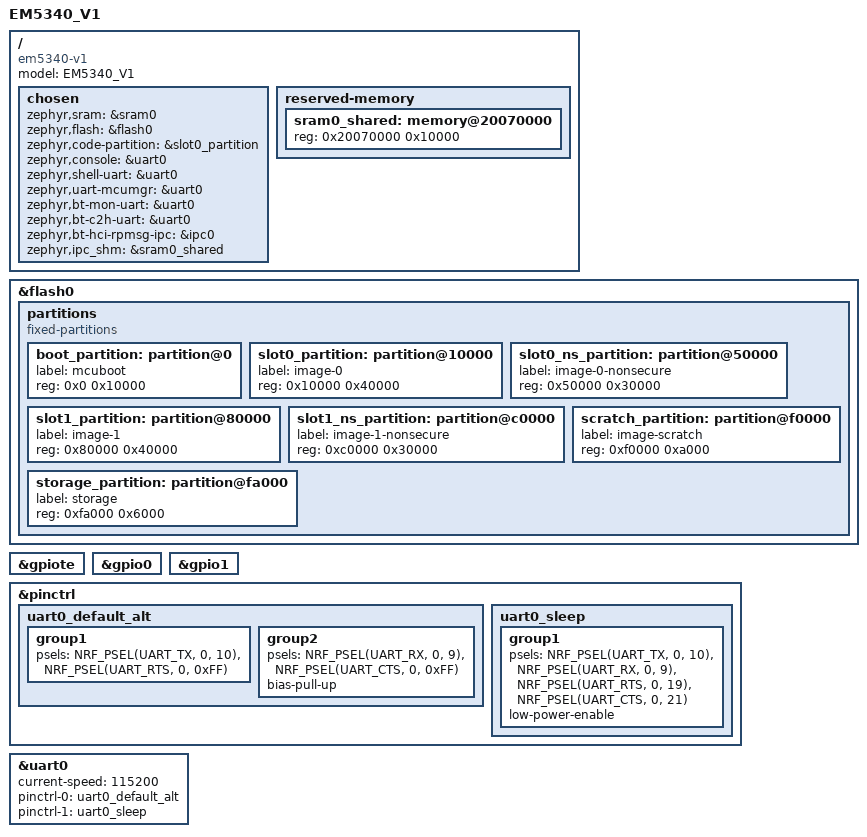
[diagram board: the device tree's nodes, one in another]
// Copyright (c) 2022 Nordic Semiconductor ASA
// SPDX-License-Identifier: Apache-2.0

/dts-v1/;
#include <nordic/nrf5340_cpuapp_qkaa.dtsi>

/ {
	model = "EM5340_V1";
	compatible = "em5340-v1";

	chosen {
		zephyr,sram = &sram0;
		zephyr,flash = &flash0;
		zephyr,code-partition = &slot0_partition;
		zephyr,console = &uart0;
		zephyr,shell-uart = &uart0;
		zephyr,uart-mcumgr = &uart0;
		zephyr,bt-mon-uart = &uart0;
		zephyr,bt-c2h-uart = &uart0;
		zephyr,bt-hci-rpmsg-ipc = &ipc0;
	};
};

/ {
	chosen {
		/* shared memory reserved for the inter-processor communication */
		zephyr,ipc_shm = &sram0_shared;
	};

	reserved-memory {
		#address-cells = <1>;
		#size-cells = <1>;
		ranges;

		sram0_shared: memory@20070000 {
			/* SRAM allocated to shared memory */
			reg = <0x20070000 0x10000>;
		};
	};
};

&flash0 {
	partitions {
		compatible = "fixed-partitions";
		#address-cells = <1>;
		#size-cells = <1>;

		boot_partition: partition@0 {
			label = "mcuboot";
			reg = <0x0 0x10000>;
		};
		slot0_partition: partition@10000 {
			label = "image-0";
			reg = <0x10000 0x40000>;
		};
		slot0_ns_partition: partition@50000 {
			label = "image-0-nonsecure";
			reg = <0x50000 0x30000>;
		};
		slot1_partition: partition@80000 {
			label = "image-1";
			reg = <0x80000 0x40000>;
		};
		slot1_ns_partition: partition@c0000 {
			label = "image-1-nonsecure";
			reg = <0xc0000 0x30000>;
		};
		scratch_partition: partition@f0000 {
			label = "image-scratch";
			reg = <0xf0000 0xa000>;
		};
		storage_partition: partition@fa000 {
			label = "storage";
			reg = <0xfa000 0x6000>;
		};
	};
};

&gpiote {
	status = "okay";
};

&gpio0 {
	status = "okay";
};

&gpio1 {
	status = "okay";
};

&pinctrl {
    uart0_default_alt: uart0_default_alt {
        group1 {
			psels = <NRF_PSEL(UART_TX, 0, 10)>,
				<NRF_PSEL(UART_RTS, 0, 0xFF)>;
		};
		group2 {
			psels = <NRF_PSEL(UART_RX, 0, 9)>,
				<NRF_PSEL(UART_CTS, 0, 0xFF)>;
			bias-pull-up;
		};
    };

	uart0_sleep: uart0_sleep {
		group1 {
			psels = <NRF_PSEL(UART_TX, 0, 10)>,
				<NRF_PSEL(UART_RX, 0, 9)>,
				<NRF_PSEL(UART_RTS, 0, 19)>,
				<NRF_PSEL(UART_CTS, 0, 21)>;
			low-power-enable;
		};
	};
};

&uart0 {
	status = "okay";
	current-speed = <115200>;
	pinctrl-0 = <&uart0_default_alt>;
	pinctrl-1 = <&uart0_sleep>;
	pinctrl-names = "default", "sleep";
};

